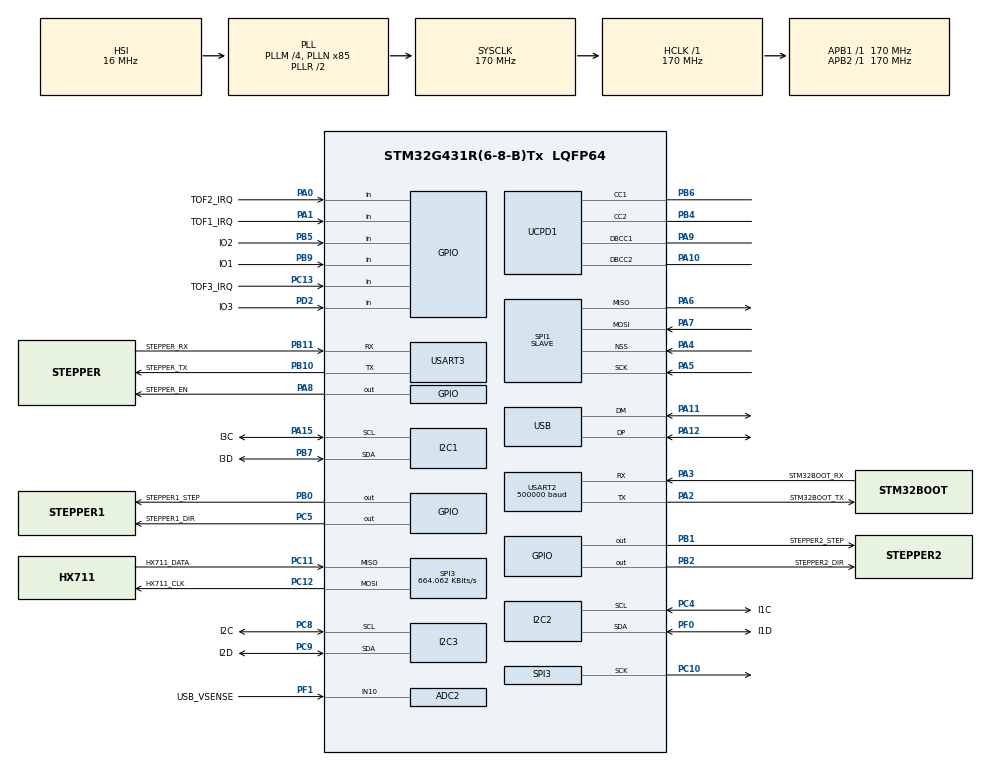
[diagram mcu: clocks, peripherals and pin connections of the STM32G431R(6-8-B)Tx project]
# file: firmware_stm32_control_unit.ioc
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ADC2.Channel-0\#ChannelRegularConversion=ADC_CHANNEL_10
ADC2.NbrOfConversionFlag=1
ADC2.OffsetNumber-0\#ChannelRegularConversion=ADC_OFFSET_NONE
ADC2.Rank-0\#ChannelRegularConversion=1
ADC2.SamplingTime-0\#ChannelRegularConversion=ADC_SAMPLETIME_2CYCLES_5
Dma.Request0=SPI3_RX
Dma.Request1=SPI3_TX
Dma.SPI3_RX.0.Direction=DMA_PERIPH_TO_MEMORY
Dma.SPI3_RX.0.EventEnable=DISABLE
Dma.SPI3_RX.0.Instance=DMA1_Channel1
Dma.SPI3_RX.0.MemDataAlignment=DMA_MDATAALIGN_BYTE
Dma.SPI3_RX.0.MemInc=DMA_MINC_ENABLE
Dma.SPI3_RX.0.Mode=DMA_NORMAL
Dma.SPI3_RX.0.PeriphDataAlignment=DMA_PDATAALIGN_BYTE
Dma.SPI3_RX.0.PeriphInc=DMA_PINC_DISABLE
Dma.SPI3_RX.0.Polarity=HAL_DMAMUX_REQ_GEN_RISING
Dma.SPI3_RX.0.Priority=DMA_PRIORITY_VERY_HIGH
Dma.SPI3_RX.0.RequestNumber=1
Dma.SPI3_RX.0.SignalID=NONE
Dma.SPI3_RX.0.SyncEnable=DISABLE
Dma.SPI3_RX.0.SyncPolarity=HAL_DMAMUX_SYNC_NO_EVENT
Dma.SPI3_RX.0.SyncRequestNumber=1
Dma.SPI3_RX.0.SyncSignalID=NONE
Dma.SPI3_TX.1.Direction=DMA_MEMORY_TO_PERIPH
Dma.SPI3_TX.1.EventEnable=DISABLE
Dma.SPI3_TX.1.Instance=DMA1_Channel2
Dma.SPI3_TX.1.MemDataAlignment=DMA_MDATAALIGN_BYTE
Dma.SPI3_TX.1.MemInc=DMA_MINC_ENABLE
Dma.SPI3_TX.1.Mode=DMA_NORMAL
Dma.SPI3_TX.1.PeriphDataAlignment=DMA_PDATAALIGN_BYTE
Dma.SPI3_TX.1.PeriphInc=DMA_PINC_DISABLE
Dma.SPI3_TX.1.Polarity=HAL_DMAMUX_REQ_GEN_RISING
Dma.SPI3_TX.1.Priority=DMA_PRIORITY_VERY_HIGH
Dma.SPI3_TX.1.RequestNumber=1
Dma.SPI3_TX.1.SignalID=NONE
Dma.SPI3_TX.1.SyncEnable=DISABLE
Dma.SPI3_TX.1.SyncPolarity=HAL_DMAMUX_SYNC_NO_EVENT
Dma.SPI3_TX.1.SyncRequestNumber=1
Dma.SPI3_TX.1.SyncSignalID=NONE
I2C1.Timing=0x40B285C2
I2C2.Timing=0x40B285C2
I2C3.Timing=0x40B285C2
Mcu.Family=STM32G4
Mcu.Name=STM32G431R(6-8-B)Tx
Mcu.Package=LQFP64
NVIC.DMA1_Channel1_IRQn=true\:0\:0\:false\:false\:true\:false\:true\:true
NVIC.DMA1_Channel2_IRQn=true\:0\:0\:false\:false\:true\:false\:true\:true
NVIC.PriorityGroup=NVIC_PRIORITYGROUP_4
NVIC.SPI3_IRQn=true\:1\:0\:true\:false\:true\:true\:true\:true
NVIC.USART2_IRQn=true\:2\:0\:true\:false\:true\:true\:true\:true
NVIC.USART3_IRQn=true\:2\:0\:true\:false\:true\:true\:true\:true
PA0.GPIO_Label=TOF2_IRQ
PA0.Signal=GPIO_Input
PA1.GPIO_Label=TOF1_IRQ
PA1.Signal=GPIO_Input
PA10.Mode=EnableDeadBattery
PA10.Signal=UCPD1_DBCC2
PA11.Mode=Device
PA11.Signal=USB_DM
PA12.Mode=Device
PA12.Signal=USB_DP
PA13.Mode=Serial_Wire
PA13.Signal=SYS_JTMS-SWDIO
PA14.Mode=Serial_Wire
PA14.Signal=SYS_JTCK-SWCLK
PA15.GPIO_Label=I3C
PA15.Mode=I2C
PA15.Signal=I2C1_SCL
PA2.GPIO_Label=STM32BOOT_TX
PA2.Mode=Asynchronous
PA2.Signal=USART2_TX
PA3.GPIO_Label=STM32BOOT_RX
PA3.Mode=Asynchronous
PA3.Signal=USART2_RX
PA4.Mode=NSS_Signal_Hard_Input
PA4.Signal=SPI1_NSS
PA5.Mode=Full_Duplex_Slave
PA5.Signal=SPI1_SCK
PA6.Mode=Full_Duplex_Slave
PA6.Signal=SPI1_MISO
PA7.Mode=Full_Duplex_Slave
PA7.Signal=SPI1_MOSI
PA8.GPIO_Label=STEPPER_EN
PA8.Signal=GPIO_Output
PA9.Mode=EnableDeadBattery
PA9.Signal=UCPD1_DBCC1
PB0.GPIO_Label=STEPPER1_STEP
PB0.Signal=GPIO_Output
PB1.GPIO_Label=STEPPER2_STEP
PB1.Signal=GPIO_Output
PB10.GPIO_Label=STEPPER_TX
PB10.Mode=Asynchronous
PB10.Signal=USART3_TX
PB11.GPIO_Label=STEPPER_RX
PB11.Mode=Asynchronous
PB11.Signal=USART3_RX
PB2.GPIO_Label=STEPPER2_DIR
PB2.Signal=GPIO_Output
PB3.Signal=SYS_JTDO-SWO
PB4.Mode=Sink_AllSignals
PB4.Signal=UCPD1_CC2
PB5.GPIO_Label=IO2
PB5.Signal=GPIO_Input
PB6.Mode=Sink_AllSignals
PB6.Signal=UCPD1_CC1
PB7.GPIO_Label=I3D
PB7.Mode=I2C
PB7.Signal=I2C1_SDA
PB9.GPIO_Label=IO1
PB9.Signal=GPIO_Input
PC10.Mode=Full_Duplex_Master
PC10.Signal=SPI3_SCK
PC11.GPIO_Label=HX711_DATA
PC11.Mode=Full_Duplex_Master
PC11.Signal=SPI3_MISO
PC12.GPIO_Label=HX711_CLK
PC12.Mode=Full_Duplex_Master
PC12.Signal=SPI3_MOSI
PC13.GPIO_Label=TOF3_IRQ
PC13.Signal=GPIO_Input
PC4.GPIO_Label=I1C
PC4.Mode=I2C
PC4.Signal=I2C2_SCL
PC5.GPIO_Label=STEPPER1_DIR
PC5.Signal=GPIO_Output
PC8.GPIO_Label=I2C
PC8.Mode=I2C
PC8.Signal=I2C3_SCL
PC9.GPIO_Label=I2D
PC9.Mode=I2C
PC9.Signal=I2C3_SDA
PD2.GPIO_Label=IO3
PD2.Signal=GPIO_Input
PF0-OSC_IN.GPIO_Label=I1D
PF0-OSC_IN.Mode=I2C
PF0-OSC_IN.Signal=I2C2_SDA
PF1-OSC_OUT.GPIO_Label=USB_VSENSE
PF1-OSC_OUT.Mode=IN10-Single-Ended
PF1-OSC_OUT.Signal=ADC2_IN10
ProjectManager.HeapSize=0x200
ProjectManager.StackSize=0x400
ProjectManager.TargetToolchain=CMake
RCC.ADC12Freq_Value=170000000
RCC.AHBFreq_Value=170000000
RCC.APB1Freq_Value=170000000
RCC.APB1TimFreq_Value=170000000
RCC.APB2Freq_Value=170000000
RCC.APB2TimFreq_Value=170000000
RCC.CK48CLockSelection=RCC_USBCLKSOURCE_HSI48
RCC.CortexFreq_Value=170000000
RCC.EXTERNAL_CLOCK_VALUE=12288000
RCC.HCLKFreq_Value=170000000
RCC.HSE_VALUE=8000000
RCC.HSI48_VALUE=48000000
RCC.HSI_VALUE=16000000
RCC.LSE_VALUE=32768
RCC.PLLM=RCC_PLLM_DIV4
RCC.PLLN=85
RCC.PLLQ=RCC_PLLQ_DIV4
RCC.SYSCLKFreq_VALUE=170000000
RCC.SYSCLKSource=RCC_SYSCLKSOURCE_PLLCLK
RCC.USBFreq_Value=48000000
RCC.VCOOutputFreq_Value=340000000
SPI1.Direction=SPI_DIRECTION_2LINES
SPI1.Mode=SPI_MODE_SLAVE
SPI1.VirtualNSS=VM_NSSHARD
SPI1.VirtualType=VM_SLAVE
SPI3.BaudRatePrescaler=SPI_BAUDRATEPRESCALER_256
SPI3.CalculateBaudRate=664.062 KBits/s
SPI3.DataSize=SPI_DATASIZE_8BIT
SPI3.Direction=SPI_DIRECTION_2LINES
SPI3.Mode=SPI_MODE_MASTER
SPI3.NSSPMode=SPI_NSS_PULSE_DISABLE
SPI3.VirtualType=VM_MASTER
USART2.BaudRate=500000
USART2.VirtualMode-Asynchronous=VM_ASYNC
USART3.VirtualMode-Asynchronous=VM_ASYNC
VP_SYS_VS_DBSignals.Mode=DisableDeadBatterySignals
VP_TIM17_VS_ClockSourceINT.Mode=Enable_Timer
VP_TIM6_VS_ClockSourceINT.Mode=Enable_Timer
VP_TIM7_VS_ClockSourceINT.Mode=Enable_Timer
board=custom

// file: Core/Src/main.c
/* USER CODE BEGIN Header */
/**
  ******************************************************************************
  * @file           : main.c
  * @brief          : Main program body
  ******************************************************************************
  * @attention
  *
  * Copyright (c) 2026 STMicroelectronics.
  * All rights reserved.
  *
  * This software is licensed under terms that can be found in the LICENSE file
  * in the root directory of this software component.
  * If no LICENSE file comes with this software, it is provided AS-IS.
  *
  ******************************************************************************
  */
/* USER CODE END Header */
#include "main.h"

/* USER CODE BEGIN Includes */
#include "app.h"

/* USER CODE END Includes */

ADC_HandleTypeDef hadc2;

I2C_HandleTypeDef hi2c1;
I2C_HandleTypeDef hi2c2;
I2C_HandleTypeDef hi2c3;

SPI_HandleTypeDef hspi1;
SPI_HandleTypeDef hspi3;
DMA_HandleTypeDef hdma_spi3_rx;
DMA_HandleTypeDef hdma_spi3_tx;

TIM_HandleTypeDef htim6;
TIM_HandleTypeDef htim7;
TIM_HandleTypeDef htim17;

UART_HandleTypeDef huart2;
UART_HandleTypeDef huart3;

PCD_HandleTypeDef hpcd_USB_FS;

void SystemClock_Config(void);
static void MX_GPIO_Init(void);
static void MX_DMA_Init(void);
static void MX_ADC2_Init(void);
static void MX_I2C1_Init(void);
static void MX_I2C2_Init(void);
static void MX_I2C3_Init(void);
static void MX_SPI1_Init(void);
static void MX_UCPD1_Init(void);
static void MX_USART2_UART_Init(void);
static void MX_USART3_UART_Init(void);
static void MX_USB_PCD_Init(void);
static void MX_TIM7_Init(void);
static void MX_TIM6_Init(void);
static void MX_TIM17_Init(void);
static void MX_SPI3_Init(void);

int main(void)
{

  /* MCU Configuration--------------------------------------------------------*/

  /* Reset of all peripherals, Initializes the Flash interface and the Systick. */
  HAL_Init();

  /* Configure the system clock */
  SystemClock_Config();

  /* Initialize all configured peripherals */
  MX_GPIO_Init();
  MX_DMA_Init();
  MX_ADC2_Init();
  MX_I2C1_Init();
  MX_I2C2_Init();
  MX_I2C3_Init();
  MX_SPI1_Init();
  MX_UCPD1_Init();
  MX_USART2_UART_Init();
  MX_USART3_UART_Init();
  MX_USB_PCD_Init();
  MX_TIM7_Init();
  MX_TIM6_Init();
  MX_TIM17_Init();
  MX_SPI3_Init();
  /* USER CODE BEGIN 2 */

  /* Initialize C++ application */
  app_setup();

  /* USER CODE END 2 */

  /* Infinite loop */
  while (1)
  {

    /* USER CODE BEGIN 3 */
    app_loop();
  }
  /* USER CODE END 3 */
}

void SystemClock_Config(void)
{
  RCC_OscInitTypeDef RCC_OscInitStruct = {0};
  RCC_ClkInitTypeDef RCC_ClkInitStruct = {0};

  /** Configure the main internal regulator output voltage
  */
  HAL_PWREx_ControlVoltageScaling(PWR_REGULATOR_VOLTAGE_SCALE1_BOOST);

  /** Initializes the RCC Oscillators according to the specified parameters
  * in the RCC_OscInitTypeDef structure.
  */
  RCC_OscInitStruct.OscillatorType = RCC_OSCILLATORTYPE_HSI|RCC_OSCILLATORTYPE_HSI48;
  RCC_OscInitStruct.HSIState = RCC_HSI_ON;
  RCC_OscInitStruct.HSICalibrationValue = RCC_HSICALIBRATION_DEFAULT;
  RCC_OscInitStruct.HSI48State = RCC_HSI48_ON;
  RCC_OscInitStruct.PLL.PLLState = RCC_PLL_ON;
  RCC_OscInitStruct.PLL.PLLSource = RCC_PLLSOURCE_HSI;
  RCC_OscInitStruct.PLL.PLLM = RCC_PLLM_DIV4;
  RCC_OscInitStruct.PLL.PLLN = 85;
  RCC_OscInitStruct.PLL.PLLP = RCC_PLLP_DIV2;
  RCC_OscInitStruct.PLL.PLLQ = RCC_PLLQ_DIV4;
  RCC_OscInitStruct.PLL.PLLR = RCC_PLLR_DIV2;
  if (HAL_RCC_OscConfig(&RCC_OscInitStruct) != HAL_OK)
  {
    Error_Handler();
  }

  /** Initializes the CPU, AHB and APB buses clocks
  */
  RCC_ClkInitStruct.ClockType = RCC_CLOCKTYPE_HCLK|RCC_CLOCKTYPE_SYSCLK
                              |RCC_CLOCKTYPE_PCLK1|RCC_CLOCKTYPE_PCLK2;
  RCC_ClkInitStruct.SYSCLKSource = RCC_SYSCLKSOURCE_PLLCLK;
  RCC_ClkInitStruct.AHBCLKDivider = RCC_SYSCLK_DIV1;
  RCC_ClkInitStruct.APB1CLKDivider = RCC_HCLK_DIV1;
  RCC_ClkInitStruct.APB2CLKDivider = RCC_HCLK_DIV1;

  if (HAL_RCC_ClockConfig(&RCC_ClkInitStruct, FLASH_LATENCY_4) != HAL_OK)
  {
    Error_Handler();
  }
}

static void MX_ADC2_Init(void)
{

  ADC_ChannelConfTypeDef sConfig = {0};

  /** Common config
  */
  hadc2.Instance = ADC2;
  hadc2.Init.ClockPrescaler = ADC_CLOCK_SYNC_PCLK_DIV4;
  hadc2.Init.Resolution = ADC_RESOLUTION_12B;
  hadc2.Init.DataAlign = ADC_DATAALIGN_RIGHT;
  hadc2.Init.GainCompensation = 0;
  hadc2.Init.ScanConvMode = ADC_SCAN_DISABLE;
  hadc2.Init.EOCSelection = ADC_EOC_SINGLE_CONV;
  hadc2.Init.LowPowerAutoWait = DISABLE;
  hadc2.Init.ContinuousConvMode = DISABLE;
  hadc2.Init.NbrOfConversion = 1;
  hadc2.Init.DiscontinuousConvMode = DISABLE;
  hadc2.Init.ExternalTrigConv = ADC_SOFTWARE_START;
  hadc2.Init.ExternalTrigConvEdge = ADC_EXTERNALTRIGCONVEDGE_NONE;
  hadc2.Init.DMAContinuousRequests = DISABLE;
  hadc2.Init.Overrun = ADC_OVR_DATA_PRESERVED;
  hadc2.Init.OversamplingMode = DISABLE;
  if (HAL_ADC_Init(&hadc2) != HAL_OK)
  {
    Error_Handler();
  }

  /** Configure Regular Channel
  */
  sConfig.Channel = ADC_CHANNEL_10;
  sConfig.Rank = ADC_REGULAR_RANK_1;
  sConfig.SamplingTime = ADC_SAMPLETIME_2CYCLES_5;
  sConfig.SingleDiff = ADC_SINGLE_ENDED;
  sConfig.OffsetNumber = ADC_OFFSET_NONE;
  sConfig.Offset = 0;
  if (HAL_ADC_ConfigChannel(&hadc2, &sConfig) != HAL_OK)
  {
    Error_Handler();
  }

}

static void MX_I2C1_Init(void)
{

  hi2c1.Instance = I2C1;
  hi2c1.Init.Timing = 0x40B285C2;
  hi2c1.Init.OwnAddress1 = 0;
  hi2c1.Init.AddressingMode = I2C_ADDRESSINGMODE_7BIT;
  hi2c1.Init.DualAddressMode = I2C_DUALADDRESS_DISABLE;
  hi2c1.Init.OwnAddress2 = 0;
  hi2c1.Init.OwnAddress2Masks = I2C_OA2_NOMASK;
  hi2c1.Init.GeneralCallMode = I2C_GENERALCALL_DISABLE;
  hi2c1.Init.NoStretchMode = I2C_NOSTRETCH_DISABLE;
  if (HAL_I2C_Init(&hi2c1) != HAL_OK)
  {
    Error_Handler();
  }

  /** Configure Analogue filter
  */
  if (HAL_I2CEx_ConfigAnalogFilter(&hi2c1, I2C_ANALOGFILTER_ENABLE) != HAL_OK)
  {
    Error_Handler();
  }

  /** Configure Digital filter
  */
  if (HAL_I2CEx_ConfigDigitalFilter(&hi2c1, 0) != HAL_OK)
  {
    Error_Handler();
  }

}

static void MX_I2C2_Init(void)
{

  hi2c2.Instance = I2C2;
  hi2c2.Init.Timing = 0x40B285C2;
  hi2c2.Init.OwnAddress1 = 0;
  hi2c2.Init.AddressingMode = I2C_ADDRESSINGMODE_7BIT;
  hi2c2.Init.DualAddressMode = I2C_DUALADDRESS_DISABLE;
  hi2c2.Init.OwnAddress2 = 0;
  hi2c2.Init.OwnAddress2Masks = I2C_OA2_NOMASK;
  hi2c2.Init.GeneralCallMode = I2C_GENERALCALL_DISABLE;
  hi2c2.Init.NoStretchMode = I2C_NOSTRETCH_DISABLE;
  if (HAL_I2C_Init(&hi2c2) != HAL_OK)
  {
    Error_Handler();
  }

  /** Configure Analogue filter
  */
  if (HAL_I2CEx_ConfigAnalogFilter(&hi2c2, I2C_ANALOGFILTER_ENABLE) != HAL_OK)
  {
    Error_Handler();
  }

  /** Configure Digital filter
  */
  if (HAL_I2CEx_ConfigDigitalFilter(&hi2c2, 0) != HAL_OK)
  {
    Error_Handler();
  }

}

static void MX_I2C3_Init(void)
{

  hi2c3.Instance = I2C3;
  hi2c3.Init.Timing = 0x40B285C2;
  hi2c3.Init.OwnAddress1 = 0;
  hi2c3.Init.AddressingMode = I2C_ADDRESSINGMODE_7BIT;
  hi2c3.Init.DualAddressMode = I2C_DUALADDRESS_DISABLE;
  hi2c3.Init.OwnAddress2 = 0;
  hi2c3.Init.OwnAddress2Masks = I2C_OA2_NOMASK;
  hi2c3.Init.GeneralCallMode = I2C_GENERALCALL_DISABLE;
  hi2c3.Init.NoStretchMode = I2C_NOSTRETCH_DISABLE;
  if (HAL_I2C_Init(&hi2c3) != HAL_OK)
  {
    Error_Handler();
  }

  /** Configure Analogue filter
  */
  if (HAL_I2CEx_ConfigAnalogFilter(&hi2c3, I2C_ANALOGFILTER_ENABLE) != HAL_OK)
  {
    Error_Handler();
  }

  /** Configure Digital filter
  */
  if (HAL_I2CEx_ConfigDigitalFilter(&hi2c3, 0) != HAL_OK)
  {
    Error_Handler();
  }

}

static void MX_SPI1_Init(void)
{

  /* SPI1 parameter configuration*/
  hspi1.Instance = SPI1;
  hspi1.Init.Mode = SPI_MODE_SLAVE;
  hspi1.Init.Direction = SPI_DIRECTION_2LINES;
  hspi1.Init.DataSize = SPI_DATASIZE_4BIT;
  hspi1.Init.CLKPolarity = SPI_POLARITY_LOW;
  hspi1.Init.CLKPhase = SPI_PHASE_1EDGE;
  hspi1.Init.NSS = SPI_NSS_HARD_INPUT;
  hspi1.Init.FirstBit = SPI_FIRSTBIT_MSB;
  hspi1.Init.TIMode = SPI_TIMODE_DISABLE;
  hspi1.Init.CRCCalculation = SPI_CRCCALCULATION_DISABLE;
  hspi1.Init.CRCPolynomial = 7;
  hspi1.Init.CRCLength = SPI_CRC_LENGTH_DATASIZE;
  hspi1.Init.NSSPMode = SPI_NSS_PULSE_DISABLE;
  if (HAL_SPI_Init(&hspi1) != HAL_OK)
  {
    Error_Handler();
  }

}

static void MX_SPI3_Init(void)
{

  /* SPI3 parameter configuration*/
  hspi3.Instance = SPI3;
  hspi3.Init.Mode = SPI_MODE_MASTER;
  hspi3.Init.Direction = SPI_DIRECTION_2LINES;
  hspi3.Init.DataSize = SPI_DATASIZE_8BIT;
  hspi3.Init.CLKPolarity = SPI_POLARITY_LOW;
  hspi3.Init.CLKPhase = SPI_PHASE_1EDGE;
  hspi3.Init.NSS = SPI_NSS_SOFT;
  hspi3.Init.BaudRatePrescaler = SPI_BAUDRATEPRESCALER_256;
  hspi3.Init.FirstBit = SPI_FIRSTBIT_MSB;
  hspi3.Init.TIMode = SPI_TIMODE_DISABLE;
  hspi3.Init.CRCCalculation = SPI_CRCCALCULATION_DISABLE;
  hspi3.Init.CRCPolynomial = 7;
  hspi3.Init.CRCLength = SPI_CRC_LENGTH_DATASIZE;
  hspi3.Init.NSSPMode = SPI_NSS_PULSE_DISABLE;
  if (HAL_SPI_Init(&hspi3) != HAL_OK)
  {
    Error_Handler();
  }

}

static void MX_TIM6_Init(void)
{

  TIM_MasterConfigTypeDef sMasterConfig = {0};

  htim6.Instance = TIM6;
  htim6.Init.Prescaler = 0;
  htim6.Init.CounterMode = TIM_COUNTERMODE_UP;
  htim6.Init.Period = 65535;
  htim6.Init.AutoReloadPreload = TIM_AUTORELOAD_PRELOAD_DISABLE;
  if (HAL_TIM_Base_Init(&htim6) != HAL_OK)
  {
    Error_Handler();
  }
  sMasterConfig.MasterOutputTrigger = TIM_TRGO_RESET;
  sMasterConfig.MasterSlaveMode = TIM_MASTERSLAVEMODE_DISABLE;
  if (HAL_TIMEx_MasterConfigSynchronization(&htim6, &sMasterConfig) != HAL_OK)
  {
    Error_Handler();
  }

}

static void MX_TIM7_Init(void)
{

  TIM_MasterConfigTypeDef sMasterConfig = {0};

  htim7.Instance = TIM7;
  htim7.Init.Prescaler = 0;
  htim7.Init.CounterMode = TIM_COUNTERMODE_UP;
  htim7.Init.Period = 65535;
  htim7.Init.AutoReloadPreload = TIM_AUTORELOAD_PRELOAD_DISABLE;
  if (HAL_TIM_Base_Init(&htim7) != HAL_OK)
  {
    Error_Handler();
  }
  sMasterConfig.MasterOutputTrigger = TIM_TRGO_RESET;
  sMasterConfig.MasterSlaveMode = TIM_MASTERSLAVEMODE_DISABLE;
  if (HAL_TIMEx_MasterConfigSynchronization(&htim7, &sMasterConfig) != HAL_OK)
  {
    Error_Handler();
  }

}

static void MX_TIM17_Init(void)
{

  htim17.Instance = TIM17;
  htim17.Init.Prescaler = 0;
  htim17.Init.CounterMode = TIM_COUNTERMODE_UP;
  htim17.Init.Period = 65535;
  htim17.Init.ClockDivision = TIM_CLOCKDIVISION_DIV1;
  htim17.Init.RepetitionCounter = 0;
  htim17.Init.AutoReloadPreload = TIM_AUTORELOAD_PRELOAD_DISABLE;
  if (HAL_TIM_Base_Init(&htim17) != HAL_OK)
  {
    Error_Handler();
  }

}

static void MX_UCPD1_Init(void)
{

  LL_GPIO_InitTypeDef GPIO_InitStruct = {0};

  /* Peripheral clock enable */
  LL_APB1_GRP2_EnableClock(LL_APB1_GRP2_PERIPH_UCPD1);

  LL_AHB2_GRP1_EnableClock(LL_AHB2_GRP1_PERIPH_GPIOB);
  /**UCPD1 GPIO Configuration
  PB4   ------> UCPD1_CC2
  PB6   ------> UCPD1_CC1
  */
  GPIO_InitStruct.Pin = LL_GPIO_PIN_4;
  GPIO_InitStruct.Mode = LL_GPIO_MODE_ANALOG;
  GPIO_InitStruct.Pull = LL_GPIO_PULL_NO;
  LL_GPIO_Init(GPIOB, &GPIO_InitStruct);

  GPIO_InitStruct.Pin = LL_GPIO_PIN_6;
  GPIO_InitStruct.Mode = LL_GPIO_MODE_ANALOG;
  GPIO_InitStruct.Pull = LL_GPIO_PULL_NO;
  LL_GPIO_Init(GPIOB, &GPIO_InitStruct);

}

static void MX_USART2_UART_Init(void)
{

  huart2.Instance = USART2;
  huart2.Init.BaudRate = 500000;
  huart2.Init.WordLength = UART_WORDLENGTH_8B;
  huart2.Init.StopBits = UART_STOPBITS_1;
  huart2.Init.Parity = UART_PARITY_NONE;
  huart2.Init.Mode = UART_MODE_TX_RX;
  huart2.Init.HwFlowCtl = UART_HWCONTROL_NONE;
  huart2.Init.OverSampling = UART_OVERSAMPLING_16;
  huart2.Init.OneBitSampling = UART_ONE_BIT_SAMPLE_DISABLE;
  huart2.Init.ClockPrescaler = UART_PRESCALER_DIV1;
  huart2.AdvancedInit.AdvFeatureInit = UART_ADVFEATURE_NO_INIT;
  if (HAL_UART_Init(&huart2) != HAL_OK)
  {
    Error_Handler();
  }
  if (HAL_UARTEx_SetTxFifoThreshold(&huart2, UART_TXFIFO_THRESHOLD_1_8) != HAL_OK)
  {
    Error_Handler();
  }
  if (HAL_UARTEx_SetRxFifoThreshold(&huart2, UART_RXFIFO_THRESHOLD_1_8) != HAL_OK)
  {
    Error_Handler();
  }
  if (HAL_UARTEx_DisableFifoMode(&huart2) != HAL_OK)
  {
    Error_Handler();
  }

}

static void MX_USART3_UART_Init(void)
{

  huart3.Instance = USART3;
  huart3.Init.BaudRate = 115200;
  huart3.Init.WordLength = UART_WORDLENGTH_8B;
  huart3.Init.StopBits = UART_STOPBITS_1;
  huart3.Init.Parity = UART_PARITY_NONE;
  huart3.Init.Mode = UART_MODE_TX_RX;
  huart3.Init.HwFlowCtl = UART_HWCONTROL_NONE;
  huart3.Init.OverSampling = UART_OVERSAMPLING_16;
  huart3.Init.OneBitSampling = UART_ONE_BIT_SAMPLE_DISABLE;
  huart3.Init.ClockPrescaler = UART_PRESCALER_DIV1;
  huart3.AdvancedInit.AdvFeatureInit = UART_ADVFEATURE_NO_INIT;
  if (HAL_UART_Init(&huart3) != HAL_OK)
  {
    Error_Handler();
  }
  if (HAL_UARTEx_SetTxFifoThreshold(&huart3, UART_TXFIFO_THRESHOLD_1_8) != HAL_OK)
  {
    Error_Handler();
  }
  if (HAL_UARTEx_SetRxFifoThreshold(&huart3, UART_RXFIFO_THRESHOLD_1_8) != HAL_OK)
  {
    Error_Handler();
  }
  if (HAL_UARTEx_DisableFifoMode(&huart3) != HAL_OK)
  {
    Error_Handler();
  }

}

static void MX_USB_PCD_Init(void)
{

  hpcd_USB_FS.Instance = USB;
  hpcd_USB_FS.Init.dev_endpoints = 8;
  hpcd_USB_FS.Init.speed = PCD_SPEED_FULL;
  hpcd_USB_FS.Init.phy_itface = PCD_PHY_EMBEDDED;
  hpcd_USB_FS.Init.Sof_enable = DISABLE;
  hpcd_USB_FS.Init.low_power_enable = DISABLE;
  hpcd_USB_FS.Init.lpm_enable = DISABLE;
  hpcd_USB_FS.Init.battery_charging_enable = DISABLE;
  if (HAL_PCD_Init(&hpcd_USB_FS) != HAL_OK)
  {
    Error_Handler();
  }

}

static void MX_DMA_Init(void)
{

  /* DMA controller clock enable */
  __HAL_RCC_DMAMUX1_CLK_ENABLE();
  __HAL_RCC_DMA1_CLK_ENABLE();

  /* DMA interrupt init */
  /* DMA1_Channel1_IRQn interrupt configuration */
  HAL_NVIC_SetPriority(DMA1_Channel1_IRQn, 0, 0);
  HAL_NVIC_EnableIRQ(DMA1_Channel1_IRQn);
  /* DMA1_Channel2_IRQn interrupt configuration */
  HAL_NVIC_SetPriority(DMA1_Channel2_IRQn, 0, 0);
  HAL_NVIC_EnableIRQ(DMA1_Channel2_IRQn);

}

static void MX_GPIO_Init(void)
{
  GPIO_InitTypeDef GPIO_InitStruct = {0};

  /* GPIO Ports Clock Enable */
  __HAL_RCC_GPIOC_CLK_ENABLE();
  __HAL_RCC_GPIOF_CLK_ENABLE();
  __HAL_RCC_GPIOA_CLK_ENABLE();
  __HAL_RCC_GPIOB_CLK_ENABLE();
  __HAL_RCC_GPIOD_CLK_ENABLE();

  /*Configure GPIO pin Output Level */
  HAL_GPIO_WritePin(STEPPER1_DIR_GPIO_Port, STEPPER1_DIR_Pin, GPIO_PIN_RESET);

  /*Configure GPIO pin Output Level */
  HAL_GPIO_WritePin(GPIOB, STEPPER1_STEP_Pin|STEPPER2_STEP_Pin|STEPPER2_DIR_Pin, GPIO_PIN_RESET);

  /*Configure GPIO pin Output Level */
  HAL_GPIO_WritePin(STEPPER_EN_GPIO_Port, STEPPER_EN_Pin, GPIO_PIN_RESET);

  /*Configure GPIO pin : TOF3_IRQ_Pin */
  GPIO_InitStruct.Pin = TOF3_IRQ_Pin;
  GPIO_InitStruct.Mode = GPIO_MODE_INPUT;
  GPIO_InitStruct.Pull = GPIO_NOPULL;
  HAL_GPIO_Init(TOF3_IRQ_GPIO_Port, &GPIO_InitStruct);

  /*Configure GPIO pins : TOF2_IRQ_Pin TOF1_IRQ_Pin */
  GPIO_InitStruct.Pin = TOF2_IRQ_Pin|TOF1_IRQ_Pin;
  GPIO_InitStruct.Mode = GPIO_MODE_INPUT;
  GPIO_InitStruct.Pull = GPIO_NOPULL;
  HAL_GPIO_Init(GPIOA, &GPIO_InitStruct);

  /*Configure GPIO pin : STEPPER1_DIR_Pin */
  GPIO_InitStruct.Pin = STEPPER1_DIR_Pin;
  GPIO_InitStruct.Mode = GPIO_MODE_OUTPUT_PP;
  GPIO_InitStruct.Pull = GPIO_NOPULL;
  GPIO_InitStruct.Speed = GPIO_SPEED_FREQ_LOW;
  HAL_GPIO_Init(STEPPER1_DIR_GPIO_Port, &GPIO_InitStruct);

  /*Configure GPIO pins : STEPPER1_STEP_Pin STEPPER2_STEP_Pin STEPPER2_DIR_Pin */
  GPIO_InitStruct.Pin = STEPPER1_STEP_Pin|STEPPER2_STEP_Pin|STEPPER2_DIR_Pin;
  GPIO_InitStruct.Mode = GPIO_MODE_OUTPUT_PP;
  GPIO_InitStruct.Pull = GPIO_NOPULL;
  GPIO_InitStruct.Speed = GPIO_SPEED_FREQ_LOW;
  HAL_GPIO_Init(GPIOB, &GPIO_InitStruct);

  /*Configure GPIO pin : STEPPER_EN_Pin */
  GPIO_InitStruct.Pin = STEPPER_EN_Pin;
  GPIO_InitStruct.Mode = GPIO_MODE_OUTPUT_PP;
  GPIO_InitStruct.Pull = GPIO_NOPULL;
  GPIO_InitStruct.Speed = GPIO_SPEED_FREQ_LOW;
  HAL_GPIO_Init(STEPPER_EN_GPIO_Port, &GPIO_InitStruct);

  /*Configure GPIO pin : IO3_Pin */
  GPIO_InitStruct.Pin = IO3_Pin;
  GPIO_InitStruct.Mode = GPIO_MODE_INPUT;
  GPIO_InitStruct.Pull = GPIO_NOPULL;
  HAL_GPIO_Init(IO3_GPIO_Port, &GPIO_InitStruct);

  /*Configure GPIO pins : IO2_Pin IO1_Pin */
  GPIO_InitStruct.Pin = IO2_Pin|IO1_Pin;
  GPIO_InitStruct.Mode = GPIO_MODE_INPUT;
  GPIO_InitStruct.Pull = GPIO_NOPULL;
  HAL_GPIO_Init(GPIOB, &GPIO_InitStruct);

}

void Error_Handler(void)
{
  __disable_irq();
  while (1)
  {
  }
}
